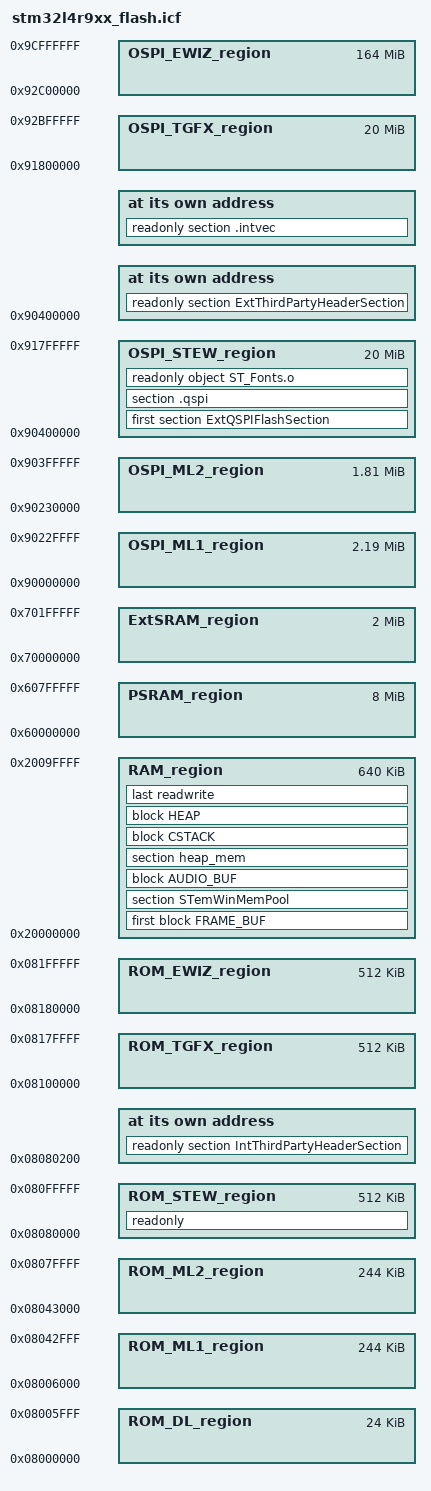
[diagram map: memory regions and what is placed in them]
/*###ICF### Section handled by ICF editor, don't touch! ****/
/*-Editor annotation file-*/
/* IcfEditorFile="$TOOLKIT_DIR$\config\ide\IcfEditor\cortex_v1_0.xml" */
/*-Specials-*/
define symbol __ICFEDIT_intvec_start__ = __C_START_ADDR;
/*-Memory Regions-*/
define symbol __ICFEDIT_region_ROM_DL_start__     = 0x08000000;
define symbol __ICFEDIT_region_ROM_DL_end__       = 0x08005FFF; /*  24 Kbytes for DemoLoader */
define symbol __ICFEDIT_region_ROM_ML1_start__    = 0x08006000;
define symbol __ICFEDIT_region_ROM_ML1_end__      = 0x08042FFF; /* 244 bytes for the MB1314 MenuLauncher */
define symbol __ICFEDIT_region_ROM_ML2_start__    = 0x08043000;
define symbol __ICFEDIT_region_ROM_ML2_end__      = 0x0807FFFF; /* 244 bytes for the MB1315 MenuLauncher */
define symbol __ICFEDIT_region_ROM_STEW_start__   = 0x08080000;
define symbol __ICFEDIT_region_ROM_STEW_end__     = 0x080FFFFF; /* 512 Kbytes for STemWin demo */
define symbol __ICFEDIT_region_ROM_TGFX_start__   = 0x08100000;
define symbol __ICFEDIT_region_ROM_TGFX_end__     = 0x0817FFFF; /* 512 Kbytes for TouchGFX demo */
define symbol __ICFEDIT_region_ROM_EWIZ_start__   = 0x08180000;
define symbol __ICFEDIT_region_ROM_EWIZ_end__     = 0x081FFFFF; /* 512 Kbytes for EmbeddedWizard demo */

/*-Internal RAM Memory Regions-*/
define symbol __ICFEDIT_region_RAM_start__        = 0x20000000; /* 640 Kbytes */
define symbol __ICFEDIT_region_RAM_end__          = 0x2009FFFF;

/*-External RAM Memory Regions-*/
define symbol __ICFEDIT_region_PSRAM_start__      = 0x60000000; /*   8 Mbytes */
define symbol __ICFEDIT_region_PSRAM_end__        = 0x607FFFFF;
define symbol __ICFEDIT_region_ExtSRAM_start__    = 0x70000000; /*   2 Mbytes */
define symbol __ICFEDIT_region_ExtSRAM_end__      = 0x701FFFFF;

/*-Octo-SPI Memory Regions-*/
define symbol __ICFEDIT_region_OSPI_ML1_start__   = 0x90000000;
define symbol __ICFEDIT_region_OSPI_ML1_end__     = 0x9022FFFF; /*  2,24 Mbytes for the MB1314 MenuLauncher assets */
define symbol __ICFEDIT_region_OSPI_ML2_start__   = 0x90230000;
define symbol __ICFEDIT_region_OSPI_ML2_end__     = 0x903FFFFF; /*  1,76 Mbytes for the MB1315 MenuLauncher assets */
define symbol __ICFEDIT_region_OSPI_STEW_start__  = 0x90400000;
define symbol __ICFEDIT_region_OSPI_STEW_end__    = 0x917FFFFF; /* 20 Mbytes for STemWin demo */
define symbol __ICFEDIT_region_OSPI_TGFX_start__  = 0x91800000;
define symbol __ICFEDIT_region_OSPI_TGFX_end__    = 0x92BFFFFF; /* 20 Mbytes for TouchGFX demo */
define symbol __ICFEDIT_region_OSPI_EWIZ_start__  = 0x92C00000;
define symbol __ICFEDIT_region_OSPI_EWIZ_end__    = 0x9CFFFFFF; /* 20 Mbytes for EmbeddedWizard demo */

/*-Sizes-*/
define symbol __ICFEDIT_size_cstack__ = 0x400;   /*  1 Kb */
define symbol __ICFEDIT_size_heap__   = 0x4400;  /* 17 Kb */
/**** End of ICF editor section. ###ICF###*/

define memory mem with size = 4G;
define region ROM_DL_region     = mem:[from __ICFEDIT_region_ROM_DL_start__     to __ICFEDIT_region_ROM_DL_end__];
define region ROM_ML1_region    = mem:[from __ICFEDIT_region_ROM_ML1_start__    to __ICFEDIT_region_ROM_ML1_end__];
define region ROM_ML2_region    = mem:[from __ICFEDIT_region_ROM_ML2_start__    to __ICFEDIT_region_ROM_ML2_end__];
define region ROM_STEW_region   = mem:[from __ICFEDIT_region_ROM_STEW_start__   to __ICFEDIT_region_ROM_STEW_end__];
define region ROM_TGFX_region   = mem:[from __ICFEDIT_region_ROM_TGFX_start__   to __ICFEDIT_region_ROM_TGFX_end__];
define region ROM_EWIZ_region   = mem:[from __ICFEDIT_region_ROM_EWIZ_start__   to __ICFEDIT_region_ROM_EWIZ_end__];

define region RAM_region        = mem:[from __ICFEDIT_region_RAM_start__        to __ICFEDIT_region_RAM_end__];
define region PSRAM_region      = mem:[from __ICFEDIT_region_PSRAM_start__      to __ICFEDIT_region_PSRAM_end__];
define region ExtSRAM_region    = mem:[from __ICFEDIT_region_ExtSRAM_start__    to __ICFEDIT_region_ExtSRAM_end__];

define region OSPI_ML1_region   = mem:[from __ICFEDIT_region_OSPI_ML1_start__   to __ICFEDIT_region_OSPI_ML1_end__];
define region OSPI_ML2_region   = mem:[from __ICFEDIT_region_OSPI_ML2_start__   to __ICFEDIT_region_OSPI_ML2_end__];
define region OSPI_STEW_region  = mem:[from __ICFEDIT_region_OSPI_STEW_start__  to __ICFEDIT_region_OSPI_STEW_end__];
define region OSPI_TGFX_region  = mem:[from __ICFEDIT_region_OSPI_TGFX_start__  to __ICFEDIT_region_OSPI_TGFX_end__];
define region OSPI_EWIZ_region  = mem:[from __ICFEDIT_region_OSPI_EWIZ_start__  to __ICFEDIT_region_OSPI_EWIZ_end__];

define block CSTACK     with alignment = 8, size = __ICFEDIT_size_cstack__    { };
define block HEAP       with alignment = 8, size = __ICFEDIT_size_heap__      { };
define block FRAME_BUF  with alignment = 32                                   { first section framebuffer };
define block AUDIO_BUF  with alignment = 16                                   { first section audio_buffers };

/*-Third Party Demonstration Headers-*/
define symbol __thp_int_header_start__ = __ICFEDIT_region_ROM_STEW_start__ + 0x200;
define symbol __thp_ext_header_start__ = __ICFEDIT_region_OSPI_STEW_start__;
/*-Third Party headers Memory Placement-*/
place at address mem:__thp_int_header_start__   { readonly section IntThirdPartyHeaderSection };
place at address mem:__thp_ext_header_start__   { readonly section ExtThirdPartyHeaderSection };

initialize by copy { readwrite };
do not initialize  { section .noinit };

place at address mem:__ICFEDIT_intvec_start__ { readonly section .intvec };

place in ROM_STEW_region    { readonly };
place in RAM_region         { first block FRAME_BUF, section STemWinMemPool, block AUDIO_BUF, section heap_mem, block CSTACK, block HEAP, last readwrite }; /* 640 Kb = 2*255 Kb + 64 Kb + 18 Kb + 16 Kb + 4 Kb + 2 Kb + 16 Kb */

place in OSPI_STEW_region   { first section ExtQSPIFlashSection
                            , section .qspi
                            , readonly object ST_Fonts.o };
